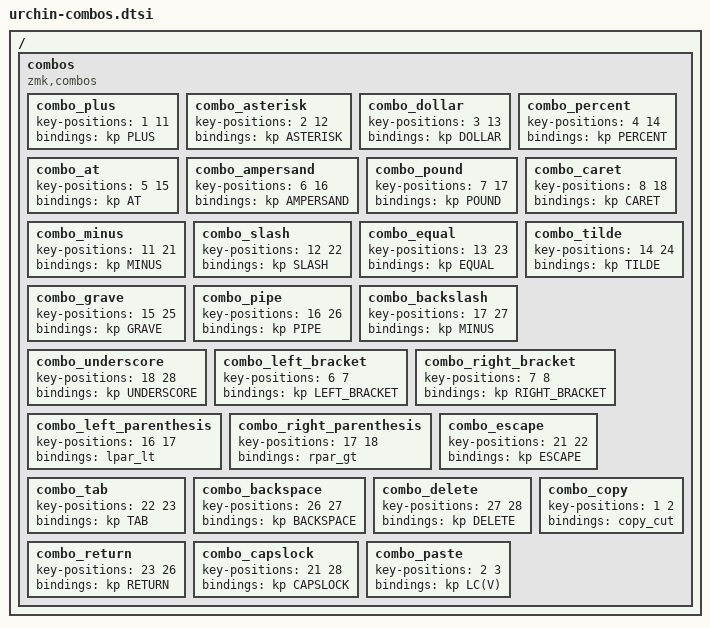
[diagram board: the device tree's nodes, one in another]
/* ┌────┬────┬────┬────┬────┐┌────┬────┬────┬────┬────┐
 * │  0 │  1 │  2 │  3 │  4 ││  5 │  6 │  7 │  8 │  9 │
 * ├────┼────┼────┼────┼────┤├────┼────┼────┼────┼────┤
 * │ 10 │ 11 │ 12 │ 13 │ 14 ││ 15 │ 16 │ 17 │ 18 │ 19 │
 * ├────┼────┼────┼────┼────┤├────┼────┼────┼────┼────┤
 * │ 20 │ 21 │ 22 │ 23 │ 24 ││ 25 │ 26 │ 27 │ 28 │ 29 │
 * └────┴────┴────┼────┼────┤├────┼────┼────┴────┴────┘
 *                │ 30 │ 31 ││ 32 │ 33 │
 *                └────┴────┘└────┴────┘
 */

/ {
  combos {
    compatible = "zmk,combos";

    // + * $ %     @ & # ^
    combo_plus {
      key-positions = <1 11>;
      bindings = <&kp PLUS>;
    };
    combo_asterisk {
      key-positions = <2 12>;
      bindings = <&kp ASTERISK>;
    };
    combo_dollar {
      key-positions = <3 13>;
      bindings = <&kp DOLLAR>;
    };
    combo_percent {
      key-positions = <4 14>;
      bindings = <&kp PERCENT>;
    };
    combo_at {
      key-positions = <5 15>;
      bindings = <&kp AT>;
    };
    combo_ampersand {
      key-positions = <6 16>;
      bindings = <&kp AMPERSAND>;
    };
    combo_pound {
      key-positions = <7 17>;
      bindings = <&kp POUND>;
    };
    combo_caret {
      key-positions = <8 18>;
      bindings = <&kp CARET>;
    };

    // - / = ~     ` | \ _
    combo_minus {
      key-positions = <11 21>;
      bindings = <&kp MINUS>;
    };
    combo_slash {
      key-positions = <12 22>;
      bindings = <&kp SLASH>;
    };
    combo_equal {
      key-positions = <13 23>;
      bindings = <&kp EQUAL>;
    };
    combo_tilde {
      key-positions = <14 24>;
      bindings = <&kp TILDE>;
    };
    combo_grave {
      key-positions = <15 25>;
      bindings = <&kp GRAVE>;
    };
    combo_pipe {
      key-positions = <16 26>;
      bindings = <&kp PIPE>;
    };
    combo_backslash {
      key-positions = <17 27>;
      bindings = <&kp MINUS>;
    };
    combo_underscore {
      key-positions = <18 28>;
      bindings = <&kp UNDERSCORE>;
    };

    combo_left_bracket {
      key-positions = <6 7>;
      bindings = <&kp LEFT_BRACKET>;
    };
    combo_right_bracket {
      key-positions = <7 8>;
      bindings = <&kp RIGHT_BRACKET>;
    };
    combo_left_parenthesis {
      key-positions = <16 17>;
      bindings = <&lpar_lt>;
    };
    combo_right_parenthesis {
      key-positions = <17 18>;
      bindings = <&rpar_gt>;
    };

    combo_escape {
      key-positions = <21 22>;
      bindings = <&kp ESCAPE>;
    };
    combo_tab {
      key-positions = <22 23>;
      bindings = <&kp TAB>;
    };
    combo_backspace {
      key-positions = <26 27>;
      bindings = <&kp BACKSPACE>;
    };
    combo_delete {
      key-positions = <27 28>;
      bindings = <&kp DELETE>;
    };
    combo_return {
      key-positions = <23 26>;
      bindings = <&kp RETURN>;
    };
    combo_capslock {
      key-positions = <21 28>;
      bindings = <&kp CAPSLOCK>;
    };

    combo_copy {
      key-positions = <1 2>;
      bindings = <&copy_cut>;
    };
    combo_paste {
      key-positions = <2 3>;
      bindings = <&kp LC(V)>;
    };
  };
};
